# STM32F407 register map
File version: 1.2
CPU: CM4 r1p0, little endian, no MPU, no FPU, 4 interrupt priority bits
Registers are 32-bit, read-write, reset 0x0 unless marked. A register's access mark holds for its fields unless they carry their own. Offsets are from the block's base; [hi:lo] are bit positions; {n}, {i} and the like mark numbered series.

## RNG — Random number generator
Base 0x50060800
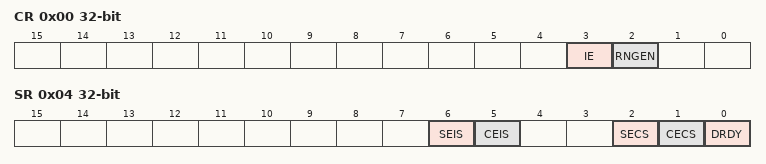
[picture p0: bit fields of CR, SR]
0x00 CR — control register
  [3] IE — Interrupt enable
    0=Disabled (RNG interrupt is disabled); 1=Enabled (RNG interrupt is enabled)
  [2] RNGEN — Random number generator enable
    0=Disabled (Random number generator is disabled); 1=Enabled (Random number generator is enabled)
0x04 SR access per field — status register
  [6] SEIS rw — Seed error interrupt status
  [5] CEIS rw — Clock error interrupt status
  [2] SECS ro — Seed error current status
  [1] CECS ro — Clock error current status
  [0] DRDY ro — Data ready
0x08 DR ro — data register
  [31:0] RNDATA — Random data

## DCMI — Digital camera interface
Base 0x50050000
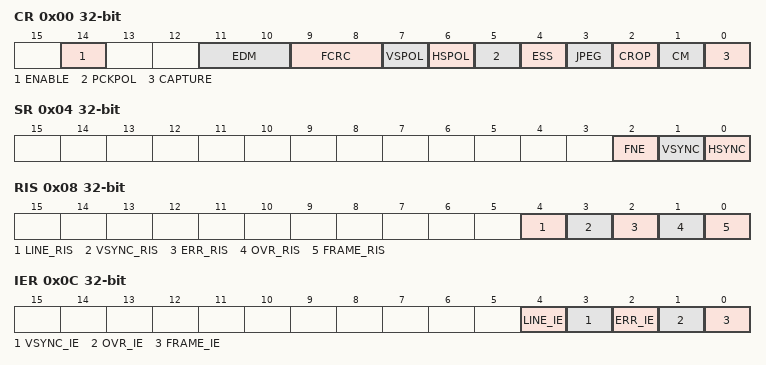
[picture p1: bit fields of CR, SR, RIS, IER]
0x00 CR — control register 1
  [14] ENABLE — DCMI enable
  [11:10] EDM — Extended data mode
  [9:8] FCRC — Frame capture rate control
  [7] VSPOL — Vertical synchronization polarity
  [6] HSPOL — Horizontal synchronization polarity
  [5] PCKPOL — Pixel clock polarity
  [4] ESS — Embedded synchronization select
  [3] JPEG — JPEG format
  [2] CROP — Crop feature
  [1] CM — Capture mode
  [0] CAPTURE — Capture enable
0x04 SR ro — status register
  [2] FNE — FIFO not empty
  [1] VSYNC
  [0] HSYNC
0x08 RIS ro — raw interrupt status register
  [4] LINE_RIS — Line raw interrupt status
  [3] VSYNC_RIS — VSYNC raw interrupt status
  [2] ERR_RIS — Synchronization error raw interrupt status
  [1] OVR_RIS — Overrun raw interrupt status
  [0] FRAME_RIS — Capture complete raw interrupt status
0x0C IER — interrupt enable register
  [4] LINE_IE — Line interrupt enable
  [3] VSYNC_IE — VSYNC interrupt enable
  [2] ERR_IE — Synchronization error interrupt enable
  [1] OVR_IE — Overrun interrupt enable
  [0] FRAME_IE — Capture complete interrupt enable
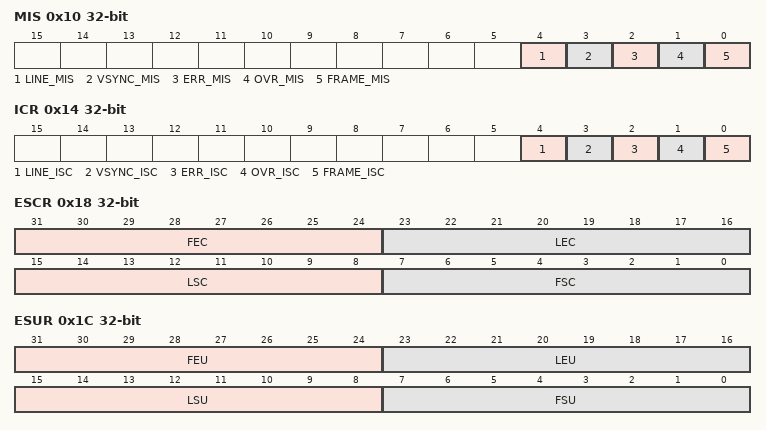
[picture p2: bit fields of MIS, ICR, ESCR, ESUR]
0x10 MIS ro — masked interrupt status register
  [4] LINE_MIS — Line masked interrupt status
  [3] VSYNC_MIS — VSYNC masked interrupt status
  [2] ERR_MIS — Synchronization error masked interrupt status
  [1] OVR_MIS — Overrun masked interrupt status
  [0] FRAME_MIS — Capture complete masked interrupt status
0x14 ICR wo — interrupt clear register
  [4] LINE_ISC — line interrupt status clear
  [3] VSYNC_ISC — Vertical synch interrupt status clear
  [2] ERR_ISC — Synchronization error interrupt status clear
  [1] OVR_ISC — Overrun interrupt status clear
  [0] FRAME_ISC — Capture complete interrupt status clear
0x18 ESCR — embedded synchronization code register
  [31:24] FEC — Frame end delimiter code
  [23:16] LEC — Line end delimiter code
  [15:8] LSC — Line start delimiter code
  [7:0] FSC — Frame start delimiter code
0x1C ESUR — embedded synchronization unmask register
  [31:24] FEU — Frame end delimiter unmask
  [23:16] LEU — Line end delimiter unmask
  [15:8] LSU — Line start delimiter unmask
  [7:0] FSU — Frame start delimiter unmask
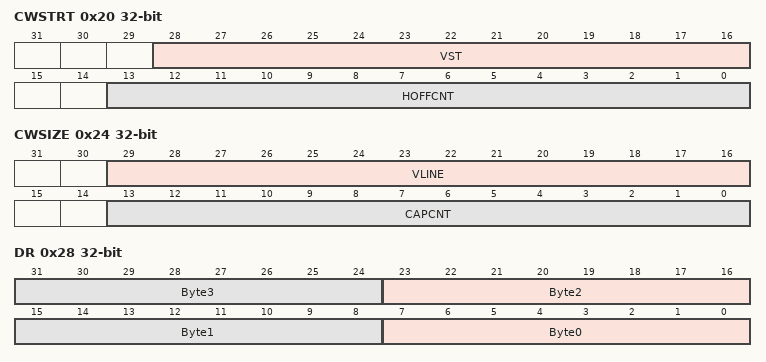
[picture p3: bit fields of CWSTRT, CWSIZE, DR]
0x20 CWSTRT — crop window start
  [28:16] VST — Vertical start line count
  [13:0] HOFFCNT — Horizontal offset count
0x24 CWSIZE — crop window size
  [29:16] VLINE — Vertical line count
  [13:0] CAPCNT — Capture count
0x28 DR ro — data register
  [8n+7:8n] Byte{n} (n=0..3) — Data byte {n}

## DBGMCU — Debug support
Base 0xE0042000
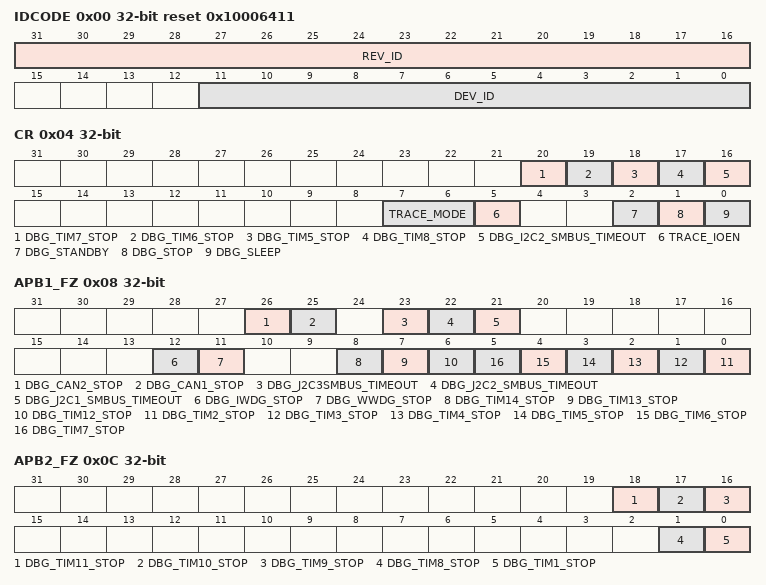
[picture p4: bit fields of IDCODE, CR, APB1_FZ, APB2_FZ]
0x00 IDCODE ro reset 0x10006411
  [31:16] REV_ID, [11:0] DEV_ID
0x04 CR — Control Register
  [20] DBG_TIM7_STOP, [19] DBG_TIM6_STOP, [18] DBG_TIM5_STOP, [17] DBG_TIM8_STOP, [16] DBG_I2C2_SMBUS_TIMEOUT, [7:6] TRACE_MODE, [5] TRACE_IOEN, [2] DBG_STANDBY, [1] DBG_STOP, [0] DBG_SLEEP
0x08 APB1_FZ — Debug MCU APB1 Freeze registe
  [26] DBG_CAN2_STOP
  [25] DBG_CAN1_STOP
  [23] DBG_J2C3SMBUS_TIMEOUT
  [22] DBG_J2C2_SMBUS_TIMEOUT
  [21] DBG_J2C1_SMBUS_TIMEOUT
  [12] DBG_IWDG_STOP — DBG_IWDEG_STOP
  [11] DBG_WWDG_STOP
  [8] DBG_TIM14_STOP
  [7] DBG_TIM13_STOP
  [6] DBG_TIM12_STOP
  [n-2] DBG_TIM{n}_STOP (n=2..7)
0x0C APB2_FZ — Debug MCU APB2 Freeze registe
  [18] DBG_TIM11_STOP — TIM11 counter stopped when core is halted
  [17] DBG_TIM10_STOP — TIM10 counter stopped when core is halted
  [16] DBG_TIM9_STOP — TIM9 counter stopped when core is halted
  [1] DBG_TIM8_STOP — TIM8 counter stopped when core is halted
  [0] DBG_TIM1_STOP — TIM1 counter stopped when core is halted
